# ETHSW register map
Registers from a debugger description file.
Registers are 32-bit, read-only, no defined reset value unless marked. A register's access mark holds for its fields unless they carry their own. Addresses are absolute; registers are grouped by the start of their names; lines under a group give offsets from that group; [hi:lo] are bit positions; {n}, {i} and the like mark numbered series; 'fields as' and 'values as' point back to an identical list; <NAME> marks a mode.

## SFR
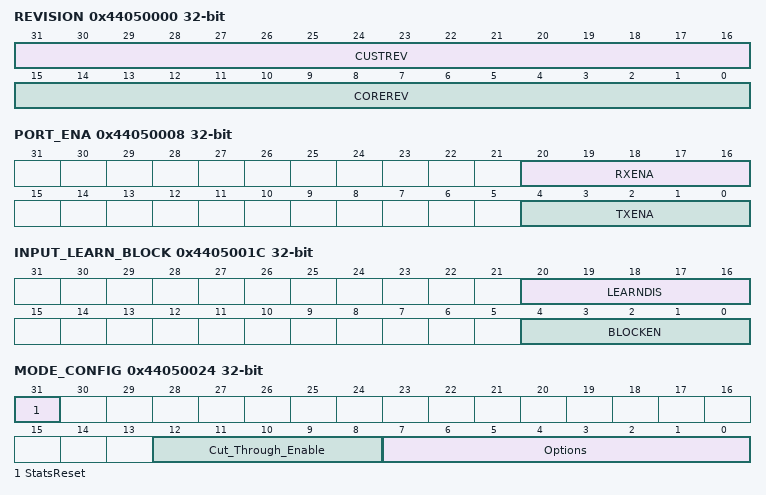
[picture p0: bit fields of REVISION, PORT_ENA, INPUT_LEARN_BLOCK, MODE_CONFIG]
0x44050000 REVISION
  [31:16] CUSTREV, [15:0] COREREV
0x44050004 SCRATCH access not given
0x44050008 PORT_ENA access not given
  [20:16] RXENA, [4:0] TXENA
0x4405000C UCAST_DEFAULT_MASK access not given
  [4:0] UCASTDM
0x4405001C INPUT_LEARN_BLOCK access not given
  [20:16] LEARNDIS, [4:0] BLOCKEN
0x44050024 MODE_CONFIG access not given
  [31] StatsReset, [12:8] Cut_Through_Enable, [7:0] Options
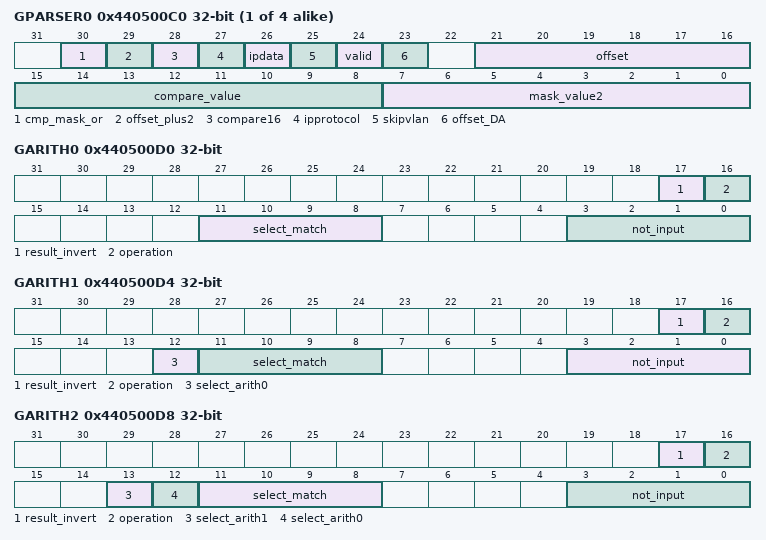
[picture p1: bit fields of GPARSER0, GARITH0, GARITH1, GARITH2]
{0x440500C0+4i} GPARSER{i} access not given (i=0..3)
  [30] cmp_mask_or, [29] offset_plus2, [28] compare16, [27] ipprotocol, [26] ipdata, [25] skipvlan, [24] valid, [23] offset_DA, [21:16] offset, [15:8] compare_value, [7:0] mask_value2
0x440500D0 GARITH0 access not given
  [17] result_invert, [16] operation, [11:8] select_match, [3:0] not_input
0x440500D4 GARITH1 access not given
  [17] result_invert, [16] operation, [12] select_arith0, [11:8] select_match, [3:0] not_input
0x440500D8 GARITH2 access not given
  [17] result_invert, [16] operation, [13] select_arith1, [12] select_arith0, [11:8] select_match, [3:0] not_input
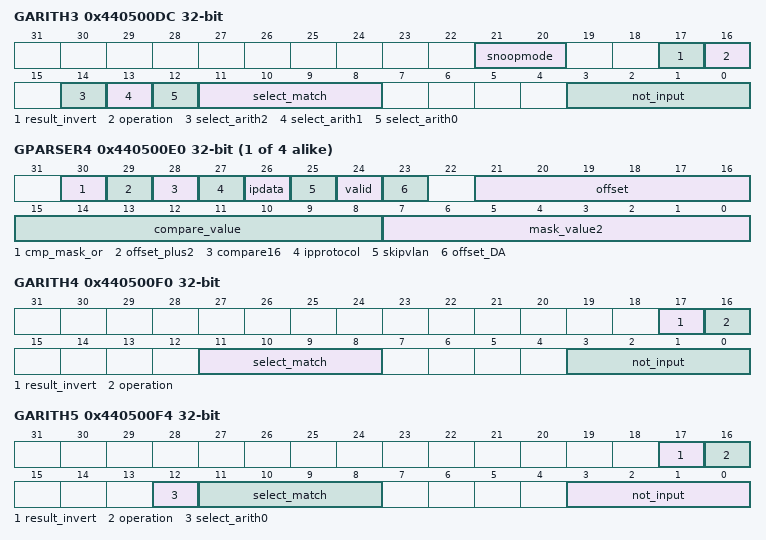
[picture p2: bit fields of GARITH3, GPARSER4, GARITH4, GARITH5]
0x440500DC GARITH3 access not given
  [21:20] snoopmode, [17] result_invert, [16] operation, [14] select_arith2, [13] select_arith1, [12] select_arith0, [11:8] select_match, [3:0] not_input
{0x440500D0+4i} GPARSER{i} access not given (i=4..7)
  fields as GPARSER0
0x440500F0 GARITH4 access not given
  fields as GARITH0
0x440500F4 GARITH5 access not given
  fields as GARITH1
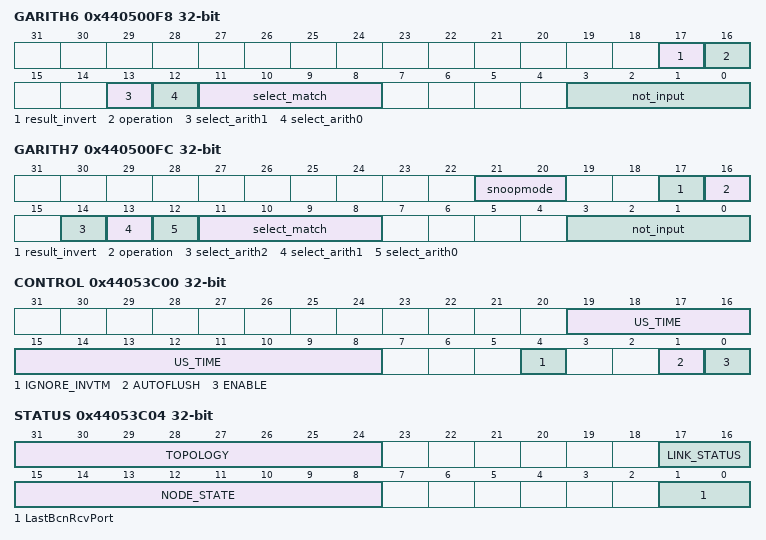
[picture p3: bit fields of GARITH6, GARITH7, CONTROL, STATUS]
0x440500F8 GARITH6 access not given
  fields as GARITH2
0x440500FC GARITH7 access not given
  fields as GARITH3
{0x44050310+0x10*i} ODISC{i} (i=0..4)
{0x4405050C+4i} PEERDELAY{i} access not given (i=0..3)
  [29:0] PEERDELAY{i}
0x44053C00 CONTROL access not given
  [19:8] US_TIME, [4] IGNORE_INVTM, [1] AUTOFLUSH, [0] ENABLE
0x44053C04 STATUS
  [31:24] TOPOLOGY, [17:16] LINK_STATUS, [15:8] NODE_STATE, [1:0] LastBcnRcvPort
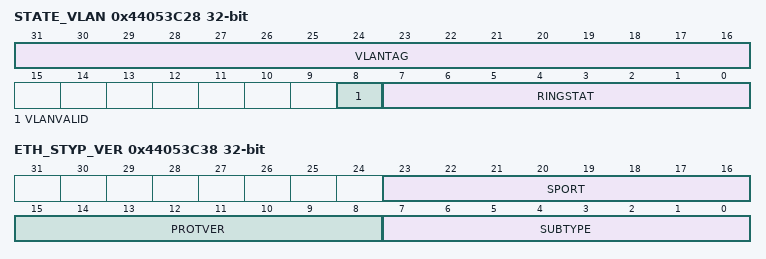
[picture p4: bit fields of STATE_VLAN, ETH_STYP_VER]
0x44053C28 STATE_VLAN
  [31:16] VLANTAG, [8] VLANVALID, [7:0] RINGSTAT
0x44053C38 ETH_STYP_VER
  [23:16] SPORT, [15:8] PROTVER, [7:0] SUBTYPE
0x44053C3C INV_TMOUT
0x44053C40 SEQ_ID
0x44053D10 DUP_W access not given
  [8:0] DUP_W
0x44053D30 TxSeqTooLate access not given
0x44053D34 CntErrWrongLanA
0x44053D38 CntErrWrongLanB
0x44053D3C CntDupLanA
0x44053D40 CntDupLanB
0x44053D44 CntOutOfSeqLowA
0x44053D48 CntOutOfSeqLowB
0x44053D4C CntOutOfSeqA
0x44053D50 CntOutOfSeqB
0x44053D54 CntAcceptA
0x44053D58 CntAcceptB
0x44053D5C CntMissing
0x44053F34 TIME_LOAD_NEXT
